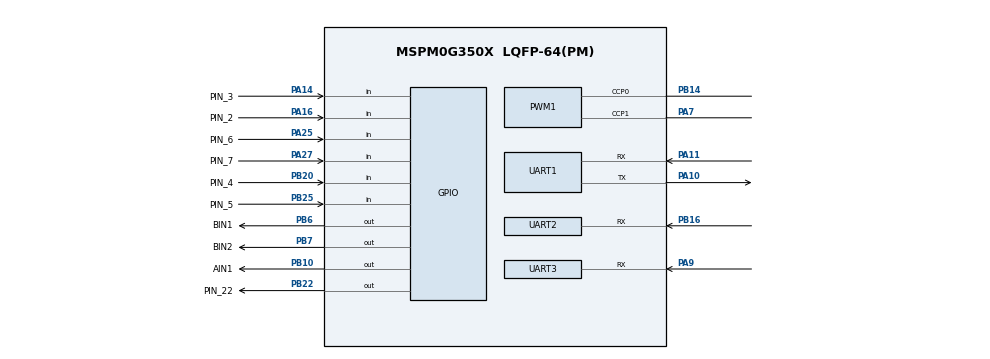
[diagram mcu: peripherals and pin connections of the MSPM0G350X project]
/**
 *
 * @cliArgs --device "MSPM0G350X" --part "Default" --package "LQFP-64(PM)" --product "mspm0_sdk@2.11.00.07"
 * @versions {"tool":"1.28.0+4696"}
 */

/**
 * Import the modules used in this configuration.
 */
const GPIO   = scripting.addModule("/ti/driverlib/GPIO", {}, false);
const GPIO1  = GPIO.addInstance();
const GPIO2  = GPIO.addInstance();
const GPIO3  = GPIO.addInstance();
const GPIO4  = GPIO.addInstance();
const PWM    = scripting.addModule("/ti/driverlib/PWM", {}, false);
const PWM1   = PWM.addInstance();
const SYSCTL = scripting.addModule("/ti/driverlib/SYSCTL");
const TIMER  = scripting.addModule("/ti/driverlib/TIMER", {}, false);
const TIMER1 = TIMER.addInstance();
const UART   = scripting.addModule("/ti/driverlib/UART", {}, false);
const UART1  = UART.addInstance();
const UART2  = UART.addInstance();
const UART3  = UART.addInstance();

/**
 * Write custom configuration values to the imported modules.
 */
const divider6       = system.clockTree["PLL_CLK2X_DIV"];
divider6.divideValue = 4;

const divider7       = system.clockTree["PLL_PDIV"];
divider7.divideValue = 2;

const divider9       = system.clockTree["UDIV"];
divider9.divideValue = 2;

const gate7  = system.clockTree["MFCLKGATE"];
gate7.enable = true;

const multiplier2         = system.clockTree["PLL_QDIV"];
multiplier2.multiplyValue = 10;

const mux4       = system.clockTree["EXHFMUX"];
mux4.inputSelect = "EXHFMUX_XTAL";

const mux8       = system.clockTree["HSCLKMUX"];
mux8.inputSelect = "HSCLKMUX_SYSPLL2X";

const pinFunction4       = system.clockTree["HFXT"];
pinFunction4.enable      = true;
pinFunction4.inputFreq   = 40;
pinFunction4.HFXTStartup = 64;

GPIO1.$name                          = "LED";
GPIO1.associatedPins[0].$name        = "PIN_22";
GPIO1.associatedPins[0].assignedPort = "PORTB";
GPIO1.associatedPins[0].assignedPin  = "22";
GPIO1.associatedPins[0].pin.$assign  = "PB22";

const Board = scripting.addModule("/ti/driverlib/Board", {}, false);

GPIO2.$name                          = "MOTOR";
GPIO2.associatedPins.create(4);
GPIO2.associatedPins[0].assignedPort = "PORTB";
GPIO2.associatedPins[0].assignedPin  = "9";
GPIO2.associatedPins[0].$name        = "AIN2";
GPIO2.associatedPins[1].$name        = "AIN1";
GPIO2.associatedPins[1].pin.$assign  = "PB10";
GPIO2.associatedPins[2].$name        = "BIN2";
GPIO2.associatedPins[2].pin.$assign  = "PB7";
GPIO2.associatedPins[3].$name        = "BIN1";
GPIO2.associatedPins[3].pin.$assign  = "PB6";

GPIO3.$name                              = "ENCODER";
GPIO3.port                               = "PORTB";
GPIO3.associatedPins.create(4);
GPIO3.associatedPins[0].$name            = "LeftA";
GPIO3.associatedPins[0].direction        = "INPUT";
GPIO3.associatedPins[0].internalResistor = "PULL_UP";
GPIO3.associatedPins[0].assignedPin      = "4";
GPIO3.associatedPins[0].interruptEn      = true;
GPIO3.associatedPins[0].polarity         = "RISE_FALL";
GPIO3.associatedPins[1].$name            = "LeftB";
GPIO3.associatedPins[1].direction        = "INPUT";
GPIO3.associatedPins[1].internalResistor = "PULL_UP";
GPIO3.associatedPins[1].assignedPin      = "5";
GPIO3.associatedPins[1].interruptEn      = true;
GPIO3.associatedPins[1].polarity         = "RISE_FALL";
GPIO3.associatedPins[2].$name            = "RightA";
GPIO3.associatedPins[2].direction        = "INPUT";
GPIO3.associatedPins[2].internalResistor = "PULL_UP";
GPIO3.associatedPins[2].assignedPin      = "11";
GPIO3.associatedPins[2].interruptEn      = true;
GPIO3.associatedPins[2].polarity         = "RISE_FALL";
GPIO3.associatedPins[3].$name            = "RightB";
GPIO3.associatedPins[3].direction        = "INPUT";
GPIO3.associatedPins[3].internalResistor = "PULL_UP";
GPIO3.associatedPins[3].assignedPin      = "12";
GPIO3.associatedPins[3].interruptEn      = true;
GPIO3.associatedPins[3].polarity         = "RISE_FALL";

GPIO4.$name                                       = "GRAY";
GPIO4.associatedPins.create(8);
GPIO4.associatedPins[0].$name                     = "PIN_0";
GPIO4.associatedPins[0].direction                 = "INPUT";
GPIO4.associatedPins[0].pin.$assignAllowConflicts = "PB19";
GPIO4.associatedPins[1].$name                     = "PIN_1";
GPIO4.associatedPins[1].direction                 = "INPUT";
GPIO4.associatedPins[1].pin.$assignAllowConflicts = "PB17";
GPIO4.associatedPins[2].$name                     = "PIN_2";
GPIO4.associatedPins[2].direction                 = "INPUT";
GPIO4.associatedPins[2].pin.$assign               = "PA16";
GPIO4.associatedPins[3].$name                     = "PIN_3";
GPIO4.associatedPins[3].direction                 = "INPUT";
GPIO4.associatedPins[3].pin.$assign               = "PA14";
GPIO4.associatedPins[4].$name                     = "PIN_4";
GPIO4.associatedPins[4].direction                 = "INPUT";
GPIO4.associatedPins[4].pin.$assign               = "PB20";
GPIO4.associatedPins[5].$name                     = "PIN_5";
GPIO4.associatedPins[5].direction                 = "INPUT";
GPIO4.associatedPins[5].pin.$assign               = "PB25";
GPIO4.associatedPins[6].$name                     = "PIN_6";
GPIO4.associatedPins[6].direction                 = "INPUT";
GPIO4.associatedPins[6].pin.$assign               = "PA25";
GPIO4.associatedPins[7].$name                     = "PIN_7";
GPIO4.associatedPins[7].direction                 = "INPUT";
GPIO4.associatedPins[7].pin.$assign               = "PA27";

PWM1.$name                      = "PWM_0";
PWM1.timerCount                 = 3200;
PWM1.timerStartTimer            = true;
PWM1.pwmMode                    = "EDGE_ALIGN_UP";
PWM1.peripheral.$assign         = "TIMA0";
PWM1.peripheral.ccp0Pin.$assign = "PB14";
PWM1.peripheral.ccp1Pin.$assign = "PA7";
PWM1.PWM_CHANNEL_0.$name        = "ti_driverlib_pwm_PWMTimerCC0";
PWM1.PWM_CHANNEL_1.$name        = "ti_driverlib_pwm_PWMTimerCC1";
PWM1.ccp0PinConfig.$name        = "ti_driverlib_gpio_GPIOPinGeneric0";
PWM1.ccp1PinConfig.$name        = "ti_driverlib_gpio_GPIOPinGeneric1";

SYSCTL.forceDefaultClkConfig = true;
SYSCTL.clockTreeEn           = true;

TIMER1.$name            = "TIMER_0";
TIMER1.timerMode        = "PERIODIC";
TIMER1.timerStartTimer  = true;
TIMER1.timerPeriod      = "1ms";
TIMER1.interrupts       = ["ZERO"];
TIMER1.timerClkDiv      = 8;
TIMER1.timerClkPrescale = 10;

UART1.$name                            = "DEBUG";
UART1.targetBaudRate                   = 115200;
UART1.rxTimeoutValue                   = 1;
UART1.rxFifoThreshold                  = "DL_UART_RX_FIFO_LEVEL_ONE_ENTRY";
UART1.txFifoThreshold                  = "DL_UART_TX_FIFO_LEVEL_3_4_EMPTY";
UART1.enabledInterrupts                = ["RX","TX"];
UART1.peripheral.rxPin.$assign         = "PA11";
UART1.peripheral.txPin.$assign         = "PA10";
UART1.txPinConfig.$name                = "ti_driverlib_gpio_GPIOPinGeneric2";
UART1.txPinConfig.direction            = scripting.forceWrite("OUTPUT");
UART1.txPinConfig.hideOutputInversion  = scripting.forceWrite(false);
UART1.txPinConfig.onlyInternalResistor = scripting.forceWrite(false);
UART1.txPinConfig.passedPeripheralType = scripting.forceWrite("Digital");
UART1.rxPinConfig.$name                = "ti_driverlib_gpio_GPIOPinGeneric3";
UART1.rxPinConfig.hideOutputInversion  = scripting.forceWrite(false);
UART1.rxPinConfig.onlyInternalResistor = scripting.forceWrite(false);
UART1.rxPinConfig.passedPeripheralType = scripting.forceWrite("Digital");

UART2.$name                            = "UART_WIT";
UART2.targetBaudRate                   = 115200;
UART2.direction                        = "RX";
UART2.enableFIFO                       = true;
UART2.enabledInterrupts                = ["RX_TIMEOUT_ERROR"];
UART2.enabledDMARXTriggers             = "DL_UART_DMA_INTERRUPT_RX";
UART2.rxTimeoutValue                   = 1;
UART2.rxPinConfig.$name                = "ti_driverlib_gpio_GPIOPinGeneric5";
UART2.rxPinConfig.hideOutputInversion  = scripting.forceWrite(false);
UART2.rxPinConfig.onlyInternalResistor = scripting.forceWrite(false);
UART2.rxPinConfig.passedPeripheralType = scripting.forceWrite("Digital");
UART2.peripheral.$assign               = "UART2";
UART2.peripheral.rxPin.$assign         = "PB16";
UART2.DMA_CHANNEL_RX.$name             = "DMA_WIT";
UART2.DMA_CHANNEL_RX.addressMode       = "f2b";
UART2.DMA_CHANNEL_RX.srcLength         = "BYTE";
UART2.DMA_CHANNEL_RX.dstLength         = "BYTE";

UART3.$name                            = "UART_K230";
UART3.targetBaudRate                   = 115200;
UART3.direction                        = "RX";
UART3.enableFIFO                       = true;
UART3.rxTimeoutValue                   = 1;
UART3.enabledInterrupts                = ["RX_TIMEOUT_ERROR"];
UART3.enabledDMARXTriggers             = "DL_UART_DMA_INTERRUPT_RX";
UART3.rxPinConfig.hideOutputInversion  = scripting.forceWrite(false);
UART3.rxPinConfig.onlyInternalResistor = scripting.forceWrite(false);
UART3.rxPinConfig.passedPeripheralType = scripting.forceWrite("Digital");
UART3.rxPinConfig.$name                = "ti_driverlib_gpio_GPIOPinGeneric6";
UART3.peripheral.rxPin.$assign         = "PA9";
UART3.DMA_CHANNEL_RX.$name             = "DMA_CH0";
UART3.DMA_CHANNEL_RX.addressMode       = "f2b";
UART3.DMA_CHANNEL_RX.srcLength         = "BYTE";
UART3.DMA_CHANNEL_RX.dstLength         = "BYTE";

/**
 * Pinmux solution for unlocked pins/peripherals. This ensures that minor changes to the automatic solver in a future
 * version of the tool will not impact the pinmux you originally saw.  These lines can be completely deleted in order to
 * re-solve from scratch.
 */
pinFunction4.peripheral.$suggestSolution           = "SYSCTL";
pinFunction4.peripheral.hfxInPin.$suggestSolution  = "PA5";
pinFunction4.peripheral.hfxOutPin.$suggestSolution = "PA6";
Board.peripheral.$suggestSolution                  = "DEBUGSS";
Board.peripheral.swclkPin.$suggestSolution         = "PA20";
Board.peripheral.swdioPin.$suggestSolution         = "PA19";
GPIO2.associatedPins[0].pin.$suggestSolution       = "PB9";
GPIO3.associatedPins[0].pin.$suggestSolution       = "PB4";
GPIO3.associatedPins[1].pin.$suggestSolution       = "PB5";
GPIO3.associatedPins[2].pin.$suggestSolution       = "PB11";
GPIO3.associatedPins[3].pin.$suggestSolution       = "PB12";
TIMER1.peripheral.$suggestSolution                 = "TIMA1";
UART1.peripheral.$suggestSolution                  = "UART0";
UART2.DMA_CHANNEL_RX.peripheral.$suggestSolution   = "DMA_CH1";
UART3.peripheral.$suggestSolution                  = "UART1";
UART3.DMA_CHANNEL_RX.peripheral.$suggestSolution   = "DMA_CH0";
